# TINY1 register map
File version: 0.1
CPU: CM3, no FPU, 3 interrupt priority bits
Registers are 32-bit, read-write, reset 0x0 unless marked. A register's access mark holds for its fields unless they carry their own. Offsets are from the block's base; lines under a group give offsets from that group; [hi:lo] are bit positions; {n}, {i} and the like mark numbered series; 'fields as' and 'values as' point back to an identical list; <NAME> marks a mode.

## Memory map
0x40008000 DMA
0x40049000 PORTA size 0x1000
0x4004A000 PORTB size 0x1000

## Interrupts
59 PORTA
60 PORTB

## PORTA
Base 0x40049000
Same registers: PORTB 0x4004A000
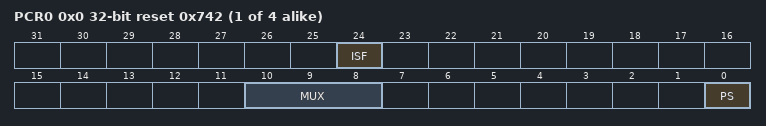
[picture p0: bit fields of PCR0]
{0x0+4i} PCR{i} (i=0..3) reset 0x742
  [24] ISF write-1-clears
  [10:8] MUX
    0=ALT0; 1=ALT1; 7=ALT7
  [0] PS
0x80 GPCLR wo
0x84 GPCHR wo
0xA0 ISFR
{0xB0+i} B[{i}] (i=0..1) 8-bit ro reset 0xA5
  [3:0] V

## DMA
Base 0x40008000
0x00 CR reset 0x400
0x1000 TCD{x} (x=A,B; step 0x20) group
  0x00 SADDR
  0x04 SOFF 16-bit reset 0x12
